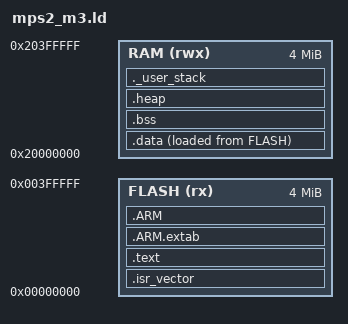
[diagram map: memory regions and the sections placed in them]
/* Linker script for the ARM Cortex-M3 MPS2 AN385 target emulated by QEMU.
 *
 * QEMU maps a 4 MB zero-based code/SRAM region at 0x00000000 (where -kernel
 * loads the image) and a further 4 MB data SRAM region at 0x20000000.
 */

MEMORY
{
    FLASH (rx)  : ORIGIN = 0x00000000, LENGTH = 0x00400000
    RAM   (rwx) : ORIGIN = 0x20000000, LENGTH = 0x00400000
}

_Min_Heap_Size  = 0x10000; /* Heap used by newlib/_sbrk (telemetry buffers). */
_Min_Stack_Size = 0x2000;  /* Startup/main + interrupt stack. */

ENTRY(Reset_Handler)

SECTIONS
{
    .isr_vector :
    {
        __vector_table = .;
        KEEP(*(.isr_vector))
        . = ALIGN(4);
    } > FLASH

    .text :
    {
        . = ALIGN(4);
        *(.text)
        *(.text*)
        *(.rodata)
        *(.rodata*)
        *(.glue_7)
        *(.glue_7t)
        KEEP(*(.init))
        KEEP(*(.fini))
        . = ALIGN(4);
        _etext = .;
    } > FLASH

    .ARM.extab :
    {
        *(.ARM.extab* .gnu.linkonce.armextab.*)
    } > FLASH

    .ARM :
    {
        __exidx_start = .;
        *(.ARM.exidx*)
        __exidx_end = .;
    } > FLASH

    _sidata = LOADADDR(.data);

    .data :
    {
        . = ALIGN(4);
        _sdata = .;
        *(.data)
        *(.data*)
        . = ALIGN(4);
        _edata = .;
    } > RAM AT > FLASH

    .bss :
    {
        . = ALIGN(4);
        _sbss = .;
        __bss_start__ = _sbss;
        *(.bss)
        *(.bss*)
        *(COMMON)
        . = ALIGN(4);
        _ebss = .;
        __bss_end__ = _ebss;
    } > RAM

    .heap :
    {
        . = ALIGN(8);
        PROVIDE ( end = . );
        PROVIDE ( _end = . );
        _heap_bottom = .;
        . = . + _Min_Heap_Size;
        _heap_top = .;
    } > RAM

    ._user_stack :
    {
        . = ALIGN(8);
        . = . + _Min_Stack_Size;
        . = ALIGN(8);
    } > RAM

    __StackTop = ORIGIN(RAM) + LENGTH(RAM);
    __StackLimit = __StackTop - _Min_Stack_Size;
    PROVIDE(__stack = __StackTop);

    ASSERT(__StackLimit >= _heap_top, "region RAM overflowed with stack")
}
